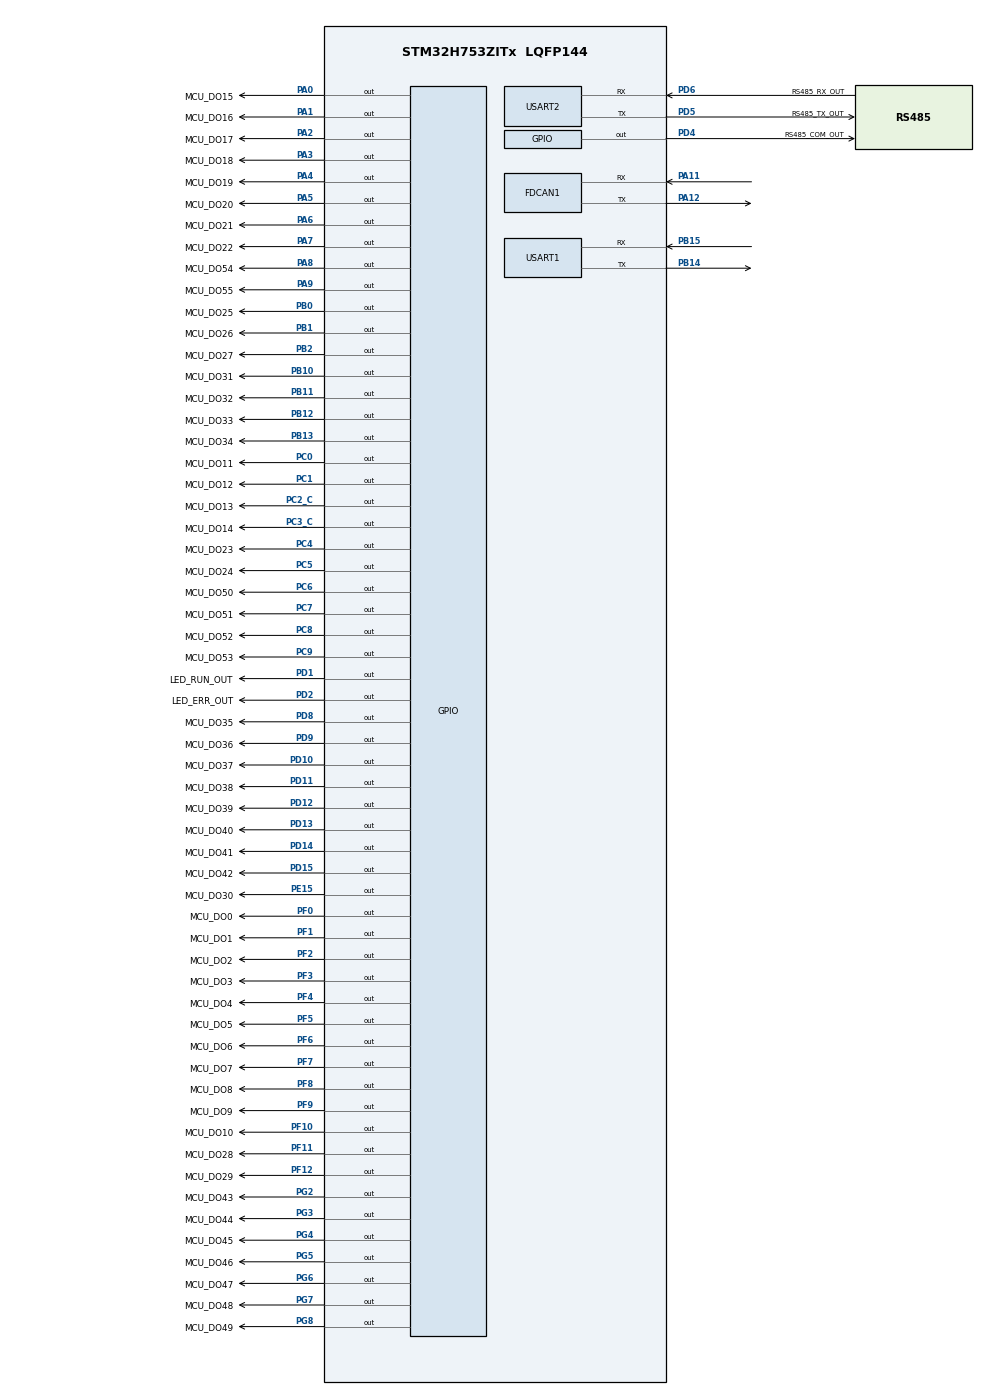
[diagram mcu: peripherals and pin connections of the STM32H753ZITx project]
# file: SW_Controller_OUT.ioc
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CORTEX_M7.default_mode_Activation=1
FDCAN1.CalculateBaudRateNominal=520833
FDCAN1.CalculateTimeBitNominal=1920
FDCAN1.CalculateTimeQuantumNominal=640.0
Mcu.Family=STM32H7
Mcu.Name=STM32H753ZITx
Mcu.Package=LQFP144
NVIC.PriorityGroup=NVIC_PRIORITYGROUP_4
NVIC.USART1_IRQn=true\:0\:0\:false\:false\:true\:true\:true\:true
NVIC.USART2_IRQn=true\:0\:0\:false\:false\:true\:true\:true\:true
PA0.GPIO_Label=MCU_DO15
PA0.Signal=GPIO_Output
PA1.GPIO_Label=MCU_DO16
PA1.Signal=GPIO_Output
PA11.Mode=FDCAN_Activate
PA11.Signal=FDCAN1_RX
PA12.Mode=FDCAN_Activate
PA12.Signal=FDCAN1_TX
PA2.GPIO_Label=MCU_DO17
PA2.Signal=GPIO_Output
PA3.GPIO_Label=MCU_DO18
PA3.Signal=GPIO_Output
PA4.GPIO_Label=MCU_DO19
PA4.Signal=GPIO_Output
PA5.GPIO_Label=MCU_DO20
PA5.Signal=GPIO_Output
PA6.GPIO_Label=MCU_DO21
PA6.Signal=GPIO_Output
PA7.GPIO_Label=MCU_DO22
PA7.Signal=GPIO_Output
PA8.GPIO_Label=MCU_DO54
PA8.Signal=GPIO_Output
PA9.GPIO_Label=MCU_DO55
PA9.Signal=GPIO_Output
PB0.GPIO_Label=MCU_DO25
PB0.Signal=GPIO_Output
PB1.GPIO_Label=MCU_DO26
PB1.Signal=GPIO_Output
PB10.GPIO_Label=MCU_DO31
PB10.Signal=GPIO_Output
PB11.GPIO_Label=MCU_DO32
PB11.Signal=GPIO_Output
PB12.GPIO_Label=MCU_DO33
PB12.Signal=GPIO_Output
PB13.GPIO_Label=MCU_DO34
PB13.Signal=GPIO_Output
PB14.Mode=Asynchronous
PB14.Signal=USART1_TX
PB15.Mode=Asynchronous
PB15.Signal=USART1_RX
PB2.GPIO_Label=MCU_DO27
PB2.Signal=GPIO_Output
PC0.GPIO_Label=MCU_DO11
PC0.Signal=GPIO_Output
PC1.GPIO_Label=MCU_DO12
PC1.Signal=GPIO_Output
PC14-OSC32_IN\ (OSC32_IN).Mode=LSE-External-Oscillator
PC14-OSC32_IN\ (OSC32_IN).Signal=RCC_OSC32_IN
PC15-OSC32_OUT\ (OSC32_OUT).Mode=LSE-External-Oscillator
PC15-OSC32_OUT\ (OSC32_OUT).Signal=RCC_OSC32_OUT
PC2_C.GPIO_Label=MCU_DO13
PC2_C.Signal=GPIO_Output
PC3_C.GPIO_Label=MCU_DO14
PC3_C.Signal=GPIO_Output
PC4.GPIO_Label=MCU_DO23
PC4.Signal=GPIO_Output
PC5.GPIO_Label=MCU_DO24
PC5.Signal=GPIO_Output
PC6.GPIO_Label=MCU_DO50
PC6.Signal=GPIO_Output
PC7.GPIO_Label=MCU_DO51
PC7.Signal=GPIO_Output
PC8.GPIO_Label=MCU_DO52
PC8.Signal=GPIO_Output
PC9.GPIO_Label=MCU_DO53
PC9.Signal=GPIO_Output
PD1.GPIO_Label=LED_RUN_OUT
PD1.Signal=GPIO_Output
PD10.GPIO_Label=MCU_DO37
PD10.Signal=GPIO_Output
PD11.GPIO_Label=MCU_DO38
PD11.Signal=GPIO_Output
PD12.GPIO_Label=MCU_DO39
PD12.Signal=GPIO_Output
PD13.GPIO_Label=MCU_DO40
PD13.Signal=GPIO_Output
PD14.GPIO_Label=MCU_DO41
PD14.Signal=GPIO_Output
PD15.GPIO_Label=MCU_DO42
PD15.Signal=GPIO_Output
PD2.GPIO_Label=LED_ERR_OUT
PD2.Signal=GPIO_Output
PD4.GPIO_Label=RS485_COM_OUT
PD4.Signal=GPIO_Output
PD5.GPIO_Label=RS485_TX_OUT
PD5.Mode=Asynchronous
PD5.Signal=USART2_TX
PD6.GPIO_Label=RS485_RX_OUT
PD6.Mode=Asynchronous
PD6.Signal=USART2_RX
PD8.GPIO_Label=MCU_DO35
PD8.Signal=GPIO_Output
PD9.GPIO_Label=MCU_DO36
PD9.Signal=GPIO_Output
PE15.GPIO_Label=MCU_DO30
PE15.Signal=GPIO_Output
PF0.GPIO_Label=MCU_DO0
PF0.Signal=GPIO_Output
PF1.GPIO_Label=MCU_DO1
PF1.Signal=GPIO_Output
PF10.GPIO_Label=MCU_DO10
PF10.Signal=GPIO_Output
PF11.GPIO_Label=MCU_DO28
PF11.Signal=GPIO_Output
PF12.GPIO_Label=MCU_DO29
PF12.Signal=GPIO_Output
PF2.GPIO_Label=MCU_DO2
PF2.Signal=GPIO_Output
PF3.GPIO_Label=MCU_DO3
PF3.Signal=GPIO_Output
PF4.GPIO_Label=MCU_DO4
PF4.Signal=GPIO_Output
PF5.GPIO_Label=MCU_DO5
PF5.Signal=GPIO_Output
PF6.GPIO_Label=MCU_DO6
PF6.Signal=GPIO_Output
PF7.GPIO_Label=MCU_DO7
PF7.Signal=GPIO_Output
PF8.GPIO_Label=MCU_DO8
PF8.Signal=GPIO_Output
PF9.GPIO_Label=MCU_DO9
PF9.Signal=GPIO_Output
PG2.GPIO_Label=MCU_DO43
PG2.Signal=GPIO_Output
PG3.GPIO_Label=MCU_DO44
PG3.Signal=GPIO_Output
PG4.GPIO_Label=MCU_DO45
PG4.Signal=GPIO_Output
PG5.GPIO_Label=MCU_DO46
PG5.Signal=GPIO_Output
PG6.GPIO_Label=MCU_DO47
PG6.Signal=GPIO_Output
PG7.GPIO_Label=MCU_DO48
PG7.Signal=GPIO_Output
PG8.GPIO_Label=MCU_DO49
PG8.Signal=GPIO_Output
PH0-OSC_IN\ (PH0).Mode=HSE-External-Oscillator
PH0-OSC_IN\ (PH0).Signal=RCC_OSC_IN
PH1-OSC_OUT\ (PH1).Mode=HSE-External-Oscillator
PH1-OSC_OUT\ (PH1).Signal=RCC_OSC_OUT
ProjectManager.HeapSize=0x200
ProjectManager.StackSize=0x400
ProjectManager.TargetToolchain=STM32CubeIDE
RCC.ADCFreq_Value=129000000
RCC.APB1Freq_Value=32000000
RCC.APB2Freq_Value=32000000
RCC.APB3Freq_Value=64000000
RCC.APB4Freq_Value=64000000
RCC.CortexFreq_Value=64000000
RCC.D2PPRE1=RCC_APB1_DIV2
RCC.D2PPRE2=RCC_APB2_DIV2
RCC.DIVM1=4
RCC.DIVN1=10
RCC.DIVQ1=3
RCC.FDCANCLockSelection=RCC_FDCANCLKSOURCE_HSE
RCC.HCLKFreq_Value=64000000
RCC.PLLFRACN=0
RCC.SYSCLKFreq_VALUE=64000000
RCC.USBFreq_Value=53333333.333333336
USART1.VirtualMode-Asynchronous=VM_ASYNC
USART2.VirtualMode-Asynchronous=VM_ASYNC
VP_MEMORYMAP_VS_MEMORYMAP.Mode=CurAppReg
board=custom

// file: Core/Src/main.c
/* USER CODE BEGIN Header */
/**
  ******************************************************************************
  * @file           : main.c
  * @brief          : Main program body
  ******************************************************************************
  * @attention
  *
  * Copyright (c) 2025 STMicroelectronics.
  * All rights reserved.
  *
  * This software is licensed under terms that can be found in the LICENSE file
  * in the root directory of this software component.
  * If no LICENSE file comes with this software, it is provided AS-IS.
  *
  ******************************************************************************
  */
/* USER CODE END Header */
#include "main.h"

/* USER CODE BEGIN Includes */
#include "version.h"
#include "debug_uart.h"
#include "rs485_protocol.h"
#include "digital_output_handler.h"
/* USER CODE END Includes */

FDCAN_HandleTypeDef hfdcan1;

UART_HandleTypeDef huart1;
UART_HandleTypeDef huart2;

/* USER CODE BEGIN PV */
static uint32_t heartbeatTimer = 0;
static uint32_t statusLedTimer = 0;
static char versionString[VERSION_STRING_SIZE];

/* Command handlers */
void HandleWriteDO(const RS485_Packet_t* packet);
void HandleReadDO(const RS485_Packet_t* packet);
/* USER CODE END PV */

void SystemClock_Config(void);
static void MPU_Config(void);
static void MX_GPIO_Init(void);
static void MX_FDCAN1_Init(void);
static void MX_USART1_UART_Init(void);
static void MX_USART2_UART_Init(void);

int main(void)
{

  /* MPU Configuration--------------------------------------------------------*/
  MPU_Config();

  /* MCU Configuration--------------------------------------------------------*/

  /* Reset of all peripherals, Initializes the Flash interface and the Systick. */
  HAL_Init();

  /* Configure the system clock */
  SystemClock_Config();

  /* Initialize all configured peripherals */
  MX_GPIO_Init();
  MX_FDCAN1_Init();
  MX_USART1_UART_Init();
  MX_USART2_UART_Init();
  /* USER CODE BEGIN 2 */

  /* Initialize hierarchical layers */
  Debug_Init();

  /* Print startup banner */
  Version_GetString(versionString, VERSION_STRING_SIZE);
  DEBUG_INFO("===========================================");
  DEBUG_INFO("  %s", versionString);
  DEBUG_INFO("===========================================");

  /* Initialize digital output handler */
  DigitalOutput_Init();

  /* Initialize RS485 protocol layer */
  RS485_Init(RS485_ADDR_CONTROLLER_OUT);

  /* Register command handlers */
  RS485_RegisterCommandHandler(CMD_WRITE_DO, HandleWriteDO);
  RS485_RegisterCommandHandler(CMD_READ_DO, HandleReadDO);

  DEBUG_INFO("System initialization complete");
  DEBUG_INFO("Entering main loop...");

  heartbeatTimer = HAL_GetTick();
  statusLedTimer = HAL_GetTick();

  /* USER CODE END 2 */

  /* Infinite loop */
  while (1)
  {

    /* USER CODE BEGIN 3 */

    /* Process RS485 communication */
    RS485_Process();

    /* Status LED blink (every 500ms) */
    if (HAL_GetTick() - statusLedTimer >= 500) {
      statusLedTimer = HAL_GetTick();
      HAL_GPIO_TogglePin(GPIOD, GPIO_PIN_1); // Status LED
    }

    /* Periodic heartbeat (verbose output disabled) */
    if (HAL_GetTick() - heartbeatTimer >= 10000) {
      heartbeatTimer = HAL_GetTick();
      // Heartbeat silently tracked
    }

    /* Small delay to prevent CPU hogging */
    HAL_Delay(1);
  }
  /* USER CODE END 3 */
}

void SystemClock_Config(void)
{
  RCC_OscInitTypeDef RCC_OscInitStruct = {0};
  RCC_ClkInitTypeDef RCC_ClkInitStruct = {0};

  /** Supply configuration update enable
  */
  HAL_PWREx_ConfigSupply(PWR_LDO_SUPPLY);

  /** Configure the main internal regulator output voltage
  */
  __HAL_PWR_VOLTAGESCALING_CONFIG(PWR_REGULATOR_VOLTAGE_SCALE3);

  while(!__HAL_PWR_GET_FLAG(PWR_FLAG_VOSRDY)) {}

  /** Initializes the RCC Oscillators according to the specified parameters
  * in the RCC_OscInitTypeDef structure.
  */
  RCC_OscInitStruct.OscillatorType = RCC_OSCILLATORTYPE_HSI|RCC_OSCILLATORTYPE_HSE;
  RCC_OscInitStruct.HSEState = RCC_HSE_ON;
  RCC_OscInitStruct.HSIState = RCC_HSI_DIV1;
  RCC_OscInitStruct.HSICalibrationValue = RCC_HSICALIBRATION_DEFAULT;
  RCC_OscInitStruct.PLL.PLLState = RCC_PLL_NONE;
  if (HAL_RCC_OscConfig(&RCC_OscInitStruct) != HAL_OK)
  {
    Error_Handler();
  }

  /** Initializes the CPU, AHB and APB buses clocks
  */
  RCC_ClkInitStruct.ClockType = RCC_CLOCKTYPE_HCLK|RCC_CLOCKTYPE_SYSCLK
                              |RCC_CLOCKTYPE_PCLK1|RCC_CLOCKTYPE_PCLK2
                              |RCC_CLOCKTYPE_D3PCLK1|RCC_CLOCKTYPE_D1PCLK1;
  RCC_ClkInitStruct.SYSCLKSource = RCC_SYSCLKSOURCE_HSI;
  RCC_ClkInitStruct.SYSCLKDivider = RCC_SYSCLK_DIV1;
  RCC_ClkInitStruct.AHBCLKDivider = RCC_HCLK_DIV1;
  RCC_ClkInitStruct.APB3CLKDivider = RCC_APB3_DIV1;
  RCC_ClkInitStruct.APB1CLKDivider = RCC_APB1_DIV2;
  RCC_ClkInitStruct.APB2CLKDivider = RCC_APB2_DIV2;
  RCC_ClkInitStruct.APB4CLKDivider = RCC_APB4_DIV1;

  if (HAL_RCC_ClockConfig(&RCC_ClkInitStruct, FLASH_LATENCY_1) != HAL_OK)
  {
    Error_Handler();
  }
}

static void MX_FDCAN1_Init(void)
{

  hfdcan1.Instance = FDCAN1;
  hfdcan1.Init.FrameFormat = FDCAN_FRAME_CLASSIC;
  hfdcan1.Init.Mode = FDCAN_MODE_NORMAL;
  hfdcan1.Init.AutoRetransmission = DISABLE;
  hfdcan1.Init.TransmitPause = DISABLE;
  hfdcan1.Init.ProtocolException = DISABLE;
  hfdcan1.Init.NominalPrescaler = 16;
  hfdcan1.Init.NominalSyncJumpWidth = 1;
  hfdcan1.Init.NominalTimeSeg1 = 1;
  hfdcan1.Init.NominalTimeSeg2 = 1;
  hfdcan1.Init.DataPrescaler = 1;
  hfdcan1.Init.DataSyncJumpWidth = 1;
  hfdcan1.Init.DataTimeSeg1 = 1;
  hfdcan1.Init.DataTimeSeg2 = 1;
  hfdcan1.Init.MessageRAMOffset = 0;
  hfdcan1.Init.StdFiltersNbr = 0;
  hfdcan1.Init.ExtFiltersNbr = 0;
  hfdcan1.Init.RxFifo0ElmtsNbr = 0;
  hfdcan1.Init.RxFifo0ElmtSize = FDCAN_DATA_BYTES_8;
  hfdcan1.Init.RxFifo1ElmtsNbr = 0;
  hfdcan1.Init.RxFifo1ElmtSize = FDCAN_DATA_BYTES_8;
  hfdcan1.Init.RxBuffersNbr = 0;
  hfdcan1.Init.RxBufferSize = FDCAN_DATA_BYTES_8;
  hfdcan1.Init.TxEventsNbr = 0;
  hfdcan1.Init.TxBuffersNbr = 0;
  hfdcan1.Init.TxFifoQueueElmtsNbr = 0;
  hfdcan1.Init.TxFifoQueueMode = FDCAN_TX_FIFO_OPERATION;
  hfdcan1.Init.TxElmtSize = FDCAN_DATA_BYTES_8;
  if (HAL_FDCAN_Init(&hfdcan1) != HAL_OK)
  {
    Error_Handler();
  }

}

static void MX_USART1_UART_Init(void)
{

  huart1.Instance = USART1;
  huart1.Init.BaudRate = 115200;
  huart1.Init.WordLength = UART_WORDLENGTH_8B;
  huart1.Init.StopBits = UART_STOPBITS_1;
  huart1.Init.Parity = UART_PARITY_NONE;
  huart1.Init.Mode = UART_MODE_TX_RX;
  huart1.Init.HwFlowCtl = UART_HWCONTROL_NONE;
  huart1.Init.OverSampling = UART_OVERSAMPLING_16;
  huart1.Init.OneBitSampling = UART_ONE_BIT_SAMPLE_DISABLE;
  huart1.Init.ClockPrescaler = UART_PRESCALER_DIV1;
  huart1.AdvancedInit.AdvFeatureInit = UART_ADVFEATURE_NO_INIT;
  if (HAL_UART_Init(&huart1) != HAL_OK)
  {
    Error_Handler();
  }
  if (HAL_UARTEx_SetTxFifoThreshold(&huart1, UART_TXFIFO_THRESHOLD_1_8) != HAL_OK)
  {
    Error_Handler();
  }
  if (HAL_UARTEx_SetRxFifoThreshold(&huart1, UART_RXFIFO_THRESHOLD_1_8) != HAL_OK)
  {
    Error_Handler();
  }
  if (HAL_UARTEx_DisableFifoMode(&huart1) != HAL_OK)
  {
    Error_Handler();
  }

}

static void MX_USART2_UART_Init(void)
{

  huart2.Instance = USART2;
  huart2.Init.BaudRate = 115200;
  huart2.Init.WordLength = UART_WORDLENGTH_8B;
  huart2.Init.StopBits = UART_STOPBITS_1;
  huart2.Init.Parity = UART_PARITY_NONE;
  huart2.Init.Mode = UART_MODE_TX_RX;
  huart2.Init.HwFlowCtl = UART_HWCONTROL_NONE;
  huart2.Init.OverSampling = UART_OVERSAMPLING_16;
  huart2.Init.OneBitSampling = UART_ONE_BIT_SAMPLE_DISABLE;
  huart2.Init.ClockPrescaler = UART_PRESCALER_DIV1;
  huart2.AdvancedInit.AdvFeatureInit = UART_ADVFEATURE_NO_INIT;
  if (HAL_UART_Init(&huart2) != HAL_OK)
  {
    Error_Handler();
  }
  if (HAL_UARTEx_SetTxFifoThreshold(&huart2, UART_TXFIFO_THRESHOLD_1_8) != HAL_OK)
  {
    Error_Handler();
  }
  if (HAL_UARTEx_SetRxFifoThreshold(&huart2, UART_RXFIFO_THRESHOLD_1_8) != HAL_OK)
  {
    Error_Handler();
  }
  if (HAL_UARTEx_DisableFifoMode(&huart2) != HAL_OK)
  {
    Error_Handler();
  }

}

static void MX_GPIO_Init(void)
{
  GPIO_InitTypeDef GPIO_InitStruct = {0};

  /* GPIO Ports Clock Enable */
  __HAL_RCC_GPIOC_CLK_ENABLE();
  __HAL_RCC_GPIOF_CLK_ENABLE();
  __HAL_RCC_GPIOH_CLK_ENABLE();
  __HAL_RCC_GPIOA_CLK_ENABLE();
  __HAL_RCC_GPIOB_CLK_ENABLE();
  __HAL_RCC_GPIOE_CLK_ENABLE();
  __HAL_RCC_GPIOD_CLK_ENABLE();
  __HAL_RCC_GPIOG_CLK_ENABLE();

  /*Configure GPIO pin Output Level */
  HAL_GPIO_WritePin(GPIOF, MCU_DO0_Pin|MCU_DO1_Pin|MCU_DO2_Pin|MCU_DO3_Pin
                          |MCU_DO4_Pin|MCU_DO5_Pin|MCU_DO6_Pin|MCU_DO7_Pin
                          |MCU_DO8_Pin|MCU_DO9_Pin|MCU_DO10_Pin|MCU_DO28_Pin
                          |MCU_DO29_Pin, GPIO_PIN_RESET);

  /*Configure GPIO pin Output Level */
  HAL_GPIO_WritePin(GPIOC, MCU_DO11_Pin|MCU_DO12_Pin|MCU_DO13_Pin|MCU_DO14_Pin
                          |MCU_DO23_Pin|MCU_DO24_Pin|MCU_DO50_Pin|MCU_DO51_Pin
                          |MCU_DO52_Pin|MCU_DO53_Pin, GPIO_PIN_RESET);

  /*Configure GPIO pin Output Level */
  HAL_GPIO_WritePin(GPIOA, MCU_DO15_Pin|MCU_DO16_Pin|MCU_DO17_Pin|MCU_DO18_Pin
                          |MCU_DO19_Pin|MCU_DO20_Pin|MCU_DO21_Pin|MCU_DO22_Pin
                          |MCU_DO54_Pin|MCU_DO55_Pin, GPIO_PIN_RESET);

  /*Configure GPIO pin Output Level */
  HAL_GPIO_WritePin(GPIOB, MCU_DO25_Pin|MCU_DO26_Pin|MCU_DO27_Pin|MCU_DO31_Pin
                          |MCU_DO32_Pin|MCU_DO33_Pin|MCU_DO34_Pin, GPIO_PIN_RESET);

  /*Configure GPIO pin Output Level */
  HAL_GPIO_WritePin(MCU_DO30_GPIO_Port, MCU_DO30_Pin, GPIO_PIN_RESET);

  /*Configure GPIO pin Output Level */
  HAL_GPIO_WritePin(GPIOD, MCU_DO35_Pin|MCU_DO36_Pin|MCU_DO37_Pin|MCU_DO38_Pin
                          |MCU_DO39_Pin|MCU_DO40_Pin|MCU_DO41_Pin|MCU_DO42_Pin
                          |LED_RUN_OUT_Pin|LED_ERR_OUT_Pin|RS485_COM_OUT_Pin, GPIO_PIN_RESET);

  /*Configure GPIO pin Output Level */
  HAL_GPIO_WritePin(GPIOG, MCU_DO43_Pin|MCU_DO44_Pin|MCU_DO45_Pin|MCU_DO46_Pin
                          |MCU_DO47_Pin|MCU_DO48_Pin|MCU_DO49_Pin, GPIO_PIN_RESET);

  /*Configure GPIO pins : MCU_DO0_Pin MCU_DO1_Pin MCU_DO2_Pin MCU_DO3_Pin
                           MCU_DO4_Pin MCU_DO5_Pin MCU_DO6_Pin MCU_DO7_Pin
                           MCU_DO8_Pin MCU_DO9_Pin MCU_DO10_Pin MCU_DO28_Pin
                           MCU_DO29_Pin */
  GPIO_InitStruct.Pin = MCU_DO0_Pin|MCU_DO1_Pin|MCU_DO2_Pin|MCU_DO3_Pin
                          |MCU_DO4_Pin|MCU_DO5_Pin|MCU_DO6_Pin|MCU_DO7_Pin
                          |MCU_DO8_Pin|MCU_DO9_Pin|MCU_DO10_Pin|MCU_DO28_Pin
                          |MCU_DO29_Pin;
  GPIO_InitStruct.Mode = GPIO_MODE_OUTPUT_PP;
  GPIO_InitStruct.Pull = GPIO_NOPULL;
  GPIO_InitStruct.Speed = GPIO_SPEED_FREQ_LOW;
  HAL_GPIO_Init(GPIOF, &GPIO_InitStruct);

  /*Configure GPIO pins : MCU_DO11_Pin MCU_DO12_Pin MCU_DO13_Pin MCU_DO14_Pin
                           MCU_DO23_Pin MCU_DO24_Pin MCU_DO50_Pin MCU_DO51_Pin
                           MCU_DO52_Pin MCU_DO53_Pin */
  GPIO_InitStruct.Pin = MCU_DO11_Pin|MCU_DO12_Pin|MCU_DO13_Pin|MCU_DO14_Pin
                          |MCU_DO23_Pin|MCU_DO24_Pin|MCU_DO50_Pin|MCU_DO51_Pin
                          |MCU_DO52_Pin|MCU_DO53_Pin;
  GPIO_InitStruct.Mode = GPIO_MODE_OUTPUT_PP;
  GPIO_InitStruct.Pull = GPIO_NOPULL;
  GPIO_InitStruct.Speed = GPIO_SPEED_FREQ_LOW;
  HAL_GPIO_Init(GPIOC, &GPIO_InitStruct);

  /*Configure GPIO pins : MCU_DO15_Pin MCU_DO16_Pin MCU_DO17_Pin MCU_DO18_Pin
                           MCU_DO19_Pin MCU_DO20_Pin MCU_DO21_Pin MCU_DO22_Pin
                           MCU_DO54_Pin MCU_DO55_Pin */
  GPIO_InitStruct.Pin = MCU_DO15_Pin|MCU_DO16_Pin|MCU_DO17_Pin|MCU_DO18_Pin
                          |MCU_DO19_Pin|MCU_DO20_Pin|MCU_DO21_Pin|MCU_DO22_Pin
                          |MCU_DO54_Pin|MCU_DO55_Pin;
  GPIO_InitStruct.Mode = GPIO_MODE_OUTPUT_PP;
  GPIO_InitStruct.Pull = GPIO_NOPULL;
  GPIO_InitStruct.Speed = GPIO_SPEED_FREQ_LOW;
  HAL_GPIO_Init(GPIOA, &GPIO_InitStruct);

  /*Configure GPIO pins : MCU_DO25_Pin MCU_DO26_Pin MCU_DO27_Pin MCU_DO31_Pin
                           MCU_DO32_Pin MCU_DO33_Pin MCU_DO34_Pin */
  GPIO_InitStruct.Pin = MCU_DO25_Pin|MCU_DO26_Pin|MCU_DO27_Pin|MCU_DO31_Pin
                          |MCU_DO32_Pin|MCU_DO33_Pin|MCU_DO34_Pin;
  GPIO_InitStruct.Mode = GPIO_MODE_OUTPUT_PP;
  GPIO_InitStruct.Pull = GPIO_NOPULL;
  GPIO_InitStruct.Speed = GPIO_SPEED_FREQ_LOW;
  HAL_GPIO_Init(GPIOB, &GPIO_InitStruct);

  /*Configure GPIO pin : MCU_DO30_Pin */
  GPIO_InitStruct.Pin = MCU_DO30_Pin;
  GPIO_InitStruct.Mode = GPIO_MODE_OUTPUT_PP;
  GPIO_InitStruct.Pull = GPIO_NOPULL;
  GPIO_InitStruct.Speed = GPIO_SPEED_FREQ_LOW;
  HAL_GPIO_Init(MCU_DO30_GPIO_Port, &GPIO_InitStruct);

  /*Configure GPIO pins : MCU_DO35_Pin MCU_DO36_Pin MCU_DO37_Pin MCU_DO38_Pin
                           MCU_DO39_Pin MCU_DO40_Pin MCU_DO41_Pin MCU_DO42_Pin
                           LED_RUN_OUT_Pin LED_ERR_OUT_Pin RS485_COM_OUT_Pin */
  GPIO_InitStruct.Pin = MCU_DO35_Pin|MCU_DO36_Pin|MCU_DO37_Pin|MCU_DO38_Pin
                          |MCU_DO39_Pin|MCU_DO40_Pin|MCU_DO41_Pin|MCU_DO42_Pin
                          |LED_RUN_OUT_Pin|LED_ERR_OUT_Pin|RS485_COM_OUT_Pin;
  GPIO_InitStruct.Mode = GPIO_MODE_OUTPUT_PP;
  GPIO_InitStruct.Pull = GPIO_NOPULL;
  GPIO_InitStruct.Speed = GPIO_SPEED_FREQ_LOW;
  HAL_GPIO_Init(GPIOD, &GPIO_InitStruct);

  /*Configure GPIO pins : MCU_DO43_Pin MCU_DO44_Pin MCU_DO45_Pin MCU_DO46_Pin
                           MCU_DO47_Pin MCU_DO48_Pin MCU_DO49_Pin */
  GPIO_InitStruct.Pin = MCU_DO43_Pin|MCU_DO44_Pin|MCU_DO45_Pin|MCU_DO46_Pin
                          |MCU_DO47_Pin|MCU_DO48_Pin|MCU_DO49_Pin;
  GPIO_InitStruct.Mode = GPIO_MODE_OUTPUT_PP;
  GPIO_InitStruct.Pull = GPIO_NOPULL;
  GPIO_InitStruct.Speed = GPIO_SPEED_FREQ_LOW;
  HAL_GPIO_Init(GPIOG, &GPIO_InitStruct);

  /*AnalogSwitch Config */
  HAL_SYSCFG_AnalogSwitchConfig(SYSCFG_SWITCH_PC2, SYSCFG_SWITCH_PC2_CLOSE);

  /*AnalogSwitch Config */
  HAL_SYSCFG_AnalogSwitchConfig(SYSCFG_SWITCH_PC3, SYSCFG_SWITCH_PC3_CLOSE);

  /*AnalogSwitch Config */
  HAL_SYSCFG_AnalogSwitchConfig(SYSCFG_SWITCH_PA0, SYSCFG_SWITCH_PA0_CLOSE);

  /*AnalogSwitch Config */
  HAL_SYSCFG_AnalogSwitchConfig(SYSCFG_SWITCH_PA1, SYSCFG_SWITCH_PA1_CLOSE);

}

/* USER CODE BEGIN 4 */

/**
 * @brief  Handle Write Digital Output command
 * @param  packet: Received packet
 * @retval None
 */
void HandleWriteDO(const RS485_Packet_t* packet)
{
    /* Set outputs from received data */
    DigitalOutput_SetAll(packet->data, packet->length);

    /* Send confirmation response */
    RS485_SendResponse(packet->srcAddr, CMD_DO_RESPONSE, NULL, 0);
}

/**
 * @brief  Handle Read Digital Output command
 * @param  packet: Received packet
 * @retval None
 */
void HandleReadDO(const RS485_Packet_t* packet)
{
    uint8_t outputData[7]; // 56 outputs = 7 bytes
    DigitalOutput_GetAll(outputData, sizeof(outputData));

    RS485_SendResponse(packet->srcAddr, CMD_DO_RESPONSE, outputData, sizeof(outputData));
}

/* USER CODE END 4 */

 /* MPU Configuration */

void MPU_Config(void)
{
  MPU_Region_InitTypeDef MPU_InitStruct = {0};

  /* Disables the MPU */
  HAL_MPU_Disable();

  /** Initializes and configures the Region and the memory to be protected
  */
  MPU_InitStruct.Enable = MPU_REGION_ENABLE;
  MPU_InitStruct.Number = MPU_REGION_NUMBER0;
  MPU_InitStruct.BaseAddress = 0x0;
  MPU_InitStruct.Size = MPU_REGION_SIZE_4GB;
  MPU_InitStruct.SubRegionDisable = 0x87;
  MPU_InitStruct.TypeExtField = MPU_TEX_LEVEL0;
  MPU_InitStruct.AccessPermission = MPU_REGION_NO_ACCESS;
  MPU_InitStruct.DisableExec = MPU_INSTRUCTION_ACCESS_DISABLE;
  MPU_InitStruct.IsShareable = MPU_ACCESS_SHAREABLE;
  MPU_InitStruct.IsCacheable = MPU_ACCESS_NOT_CACHEABLE;
  MPU_InitStruct.IsBufferable = MPU_ACCESS_NOT_BUFFERABLE;

  HAL_MPU_ConfigRegion(&MPU_InitStruct);
  /* Enables the MPU */
  HAL_MPU_Enable(MPU_PRIVILEGED_DEFAULT);

}

void Error_Handler(void)
{
  __disable_irq();
  while (1)
  {
  }
}
